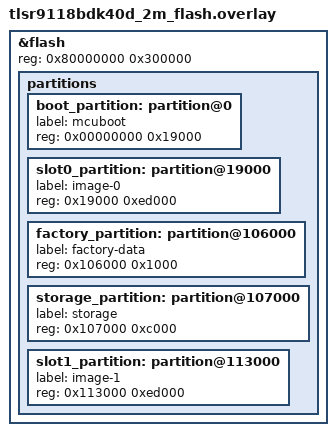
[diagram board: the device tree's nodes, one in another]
&flash {
	reg = <0x80000000 0x300000>;

	partitions {
		/delete-node/ partition@0;
		/delete-node/ partition@20000;
		/delete-node/ partition@88000;
		/delete-node/ partition@f0000;
		/delete-node/ partition@f4000;
		boot_partition: partition@0 {
			label = "mcuboot";
			reg = <0x00000000 0x19000>;
		};
		slot0_partition: partition@19000 {
			label = "image-0";
			reg = <0x19000 0xed000>;
		};
		factory_partition: partition@106000 {
			label = "factory-data";
			reg = <0x106000 0x1000>;
		};
		storage_partition: partition@107000 {
			label = "storage";
			reg = <0x107000 0xc000>;
		};
		slot1_partition: partition@113000 {
			label = "image-1";
			reg = <0x113000 0xed000>;
		};
	};
};
